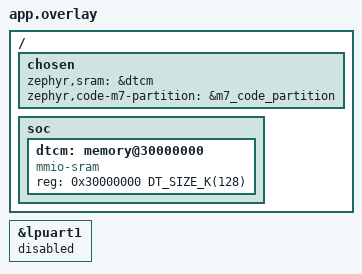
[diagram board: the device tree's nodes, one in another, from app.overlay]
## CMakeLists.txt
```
# tools/app/launcher -- the FRDM-IMXRT1186's M33 image of decision 0023: it
# boots from the NOR (the boot header and the XMCD that has the ROM set up
# the HyperRAM), opens the TRDC to the Cortex-M7 and releases it to run its
# code in place from m7_code_partition. It does nothing after that.
#
# With SPC_GEN_DIR (the build of an application with a udp: channel, decision
# 0024's amendment) it is also the network firmware: it initialises the OCRAM
# ring before the M7 is released, takes its address by DHCP, publishes the
# boot id and sends every message the M7 puts into the ring, verbatim, as one
# UDP datagram (net/README.md). SPC_GEN_DIR holds the build's generated
# spc_net.h and spc_ring_geometry.h; it is read as a sysbuild image variable
# (launcher_SPC_GEN_DIR) or a plain one. The caller also gives the image
# net/net.conf as EXTRA_CONF_FILE and net/net.overlay as
# EXTRA_DTC_OVERLAY_FILE (spinel-core-app build passes them as launcher_...).
cmake_minimum_required(VERSION 3.20.0)
set(DTC_OVERLAY_FILE "${CMAKE_CURRENT_LIST_DIR}/app.overlay;${CMAKE_CURRENT_LIST_DIR}/../zephyr/v4.4.2/boards/frdm_imxrt1186_nor.overlay")
find_package(Zephyr REQUIRED HINTS $ENV{ZEPHYR_BASE})
project(spinel_m7_launcher)
target_sources(app PRIVATE src/main.c)
zephyr_get(SPC_GEN_DIR SYSBUILD LOCAL)
if(SPC_GEN_DIR)
  if(NOT CONFIG_NETWORKING)
    message(FATAL_ERROR "SPC_GEN_DIR is given without net/net.conf: pass it as EXTRA_CONF_FILE")
  endif()
  target_sources(app PRIVATE net/ring_init.c net/forward.c)
  target_include_directories(app PRIVATE ${SPC_GEN_DIR} ${CMAKE_CURRENT_LIST_DIR}/..)
  target_compile_definitions(app PRIVATE SPC_NET_FIRMWARE=1)
  # the network code runs from the M33's ITCM: in place from the NOR a
  # datagram's send took 471 us (median), from the ITCM 173 us
  # (tools/doom/net-probe/README.md)
  foreach(lib subsys__net__ip subsys__net subsys__net__l2__ethernet subsys__net__l2__ethernet__dsa drivers__ethernet)
    zephyr_code_relocate(LIBRARY ${lib} LOCATION ITCM_TEXT NOKEEP)
  endforeach()
endif()
```

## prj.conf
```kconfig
# The launcher releases the Cortex-M7 (soc/nxp/imxrt/imxrt118x/soc.c:
# Prepare_CM7 in the reset hook, second_core_boot at PRE_KERNEL_2), whose
# code runs in place from the NOR. LPUART1 is the M7's console, so the
# launcher has none.
CONFIG_SECOND_CORE_MCUX=y
CONFIG_CM7_BOOT_FROM_FLASH=y
CONFIG_CONSOLE=n
CONFIG_UART_CONSOLE=n
CONFIG_SERIAL=n
CONFIG_PRINTK=n
CONFIG_GPIO=n
```

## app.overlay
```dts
/*
 * The launcher's own memory is its DTCM, so the HyperRAM is the M7's alone
 * (boards/nxp/frdm_imxrt1186/cm33_sram_dtcm.overlay at the pinned Zephyr),
 * and LPUART1 is left to the M7.
 */
/delete-node/ &dtcm;

/ {
	chosen {
		zephyr,sram = &dtcm;
		zephyr,code-m7-partition = &m7_code_partition;
		/delete-property/ zephyr,console;
		/delete-property/ zephyr,shell-uart;
	};

	soc {
		dtcm: memory@30000000 {
			compatible = "mmio-sram";
			reg = <0x30000000 DT_SIZE_K(128)>;
		};
	};
};

&lpuart1 {
	status = "disabled";
};
```

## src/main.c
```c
/* The launcher's work is done before main (decision 0023): the SoC's reset
 * hook and PRE_KERNEL_2 init release the Cortex-M7. As the network firmware
 * (SPC_NET_FIRMWARE, decision 0024's amendment) main then forwards the
 * ring's messages for ever (net/forward.c). */
#if defined(SPC_NET_FIRMWARE)
void spc_net_forward(void);
#endif

int main(void)
{
#if defined(SPC_NET_FIRMWARE)
	spc_net_forward();
#endif
	return 0;
}
```
